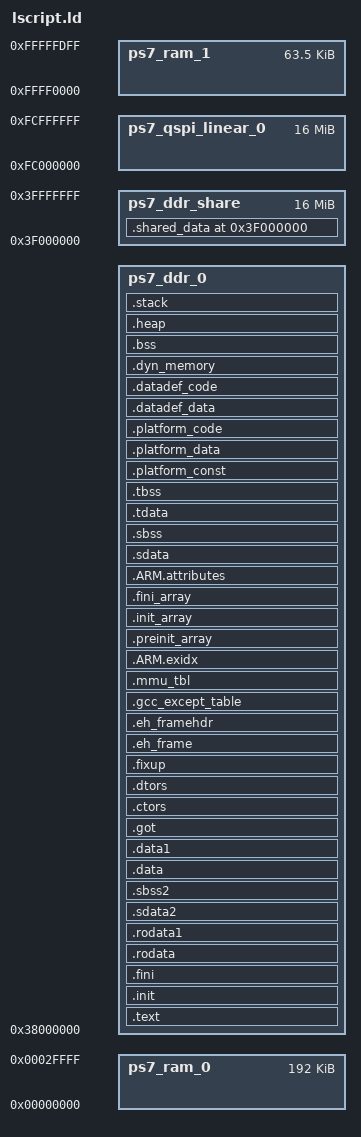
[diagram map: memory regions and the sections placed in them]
/*******************************************************************/
/*                                                                 */
/* This file is automatically generated by linker script generator.*/
/*                                                                 */
/* Version: 2018.3                                                 */
/*                                                                 */
/* Copyright (c) 2010-2016 Xilinx, Inc.  All rights reserved.      */
/*                                                                 */
/* Description : Cortex-A9 Linker Script                           */
/*                                                                 */
/*******************************************************************/

_STACK_SIZE = DEFINED(_STACK_SIZE) ? _STACK_SIZE : 0x8000;
_HEAP_SIZE = DEFINED(_HEAP_SIZE) ? _HEAP_SIZE : 0x402000;

_ABORT_STACK_SIZE = DEFINED(_ABORT_STACK_SIZE) ? _ABORT_STACK_SIZE : 4096;
_SUPERVISOR_STACK_SIZE = DEFINED(_SUPERVISOR_STACK_SIZE) ? _SUPERVISOR_STACK_SIZE : 4096;
_IRQ_STACK_SIZE = DEFINED(_IRQ_STACK_SIZE) ? _IRQ_STACK_SIZE : 8192;
_FIQ_STACK_SIZE = DEFINED(_FIQ_STACK_SIZE) ? _FIQ_STACK_SIZE : 8192;
_UNDEF_STACK_SIZE = DEFINED(_UNDEF_STACK_SIZE) ? _UNDEF_STACK_SIZE : 4096;

/*
  DDR内存空间分配
    DDR总空间 1024M，即0x40000000
    其中：
      0x00000000 ~ 0x38000000 : Linux内存 384M
      0x38000000 ~ 0x3F000000 : 裸核内存  112M
      0x3F000000 ~ 0x40000000 : 共享内存和FPGA使用的内存 16M
*/

/* 当前使用的DDR起始地址 如果这里修改了，需要同时修改bmrun.c文件*/
_CORE1_DDR_START_ADDR =         0x38000000;

/* 如果这里修改了，需要同事修改plt_pub_struct.h文件 */
_CORE1_DDR_SHART_START_ADDR =   0x3F000000;

/* 当前使用的DDR长度 112M        0x7000000 */
_CORE1_DDR_LENGTH =             (_CORE1_DDR_SHART_START_ADDR - _CORE1_DDR_START_ADDR);
/* 当前共享内存的长度 16M 这段内存不开cache 如果这里修改了，需要同时修改plt_pub_struct.h文件 */
_CORE1_DDR_SHARE_LENGTH =       0x1000000;

/*定义堆起始空间 (堆后还有栈空间)*/
_CORE1_HEAP_START_ADDR =  _CORE1_DDR_START_ADDR + _CORE1_DDR_LENGTH - 0x500000; /*最后1M空间用于heap和stack*/
/* 堆和栈之间预留空间 */



_CORE1_HEAP_RESERVE_STACK_SIZE = 0x1000;
/*定义栈起始空间 先放大_HEAP_SIZE 4M 后面考虑用mem_Malloc */
_CORE1_STACK_START_ADDR =  _CORE1_HEAP_START_ADDR + _HEAP_SIZE + _CORE1_HEAP_RESERVE_STACK_SIZE;

/* 定义平台代码各区段之间的预留空间 */
_CORE1_PLATFORM_RESERVE = 0x200;

/* Define Memories in the system */

MEMORY
{
   ps7_ddr_0 : ORIGIN = _CORE1_DDR_START_ADDR, LENGTH = _CORE1_DDR_LENGTH
   ps7_ddr_share : ORIGIN = _CORE1_DDR_SHART_START_ADDR, LENGTH = _CORE1_DDR_SHARE_LENGTH
   ps7_qspi_linear_0 : ORIGIN = 0xFC000000, LENGTH = 0x1000000
   ps7_ram_0 : ORIGIN = 0x0, LENGTH = 0x30000
   ps7_ram_1 : ORIGIN = 0xFFFF0000, LENGTH = 0xFE00
}

/* Specify the default entry point to the program */

ENTRY(_vector_table)

/* Define the sections, and where they are mapped in memory */

SECTIONS
{

.text : {
   KEEP (*(.vectors))
   *(.boot)
   *(.text)
   *(.text.*)
   *(.gnu.linkonce.t.*)
   *(.plt)
   *(.gnu_warning)
   *(.gcc_execpt_table)
   *(.glue_7)
   *(.glue_7t)
   *(.vfp11_veneer)
   *(.ARM.extab)
   *(.gnu.linkonce.armextab.*)
} > ps7_ddr_0

.init : {
   KEEP (*(.init))
} > ps7_ddr_0

.fini : {
   KEEP (*(.fini))
} > ps7_ddr_0

.rodata : {
   __rodata_start = .;
   *(.rodata)
   *(.rodata.*)
   *(.gnu.linkonce.r.*)
   __rodata_end = .;
} > ps7_ddr_0

.rodata1 : {
   __rodata1_start = .;
   *(.rodata1)
   *(.rodata1.*)
   __rodata1_end = .;
} > ps7_ddr_0

.sdata2 : {
   __sdata2_start = .;
   *(.sdata2)
   *(.sdata2.*)
   *(.gnu.linkonce.s2.*)
   __sdata2_end = .;
} > ps7_ddr_0

.sbss2 : {
   __sbss2_start = .;
   *(.sbss2)
   *(.sbss2.*)
   *(.gnu.linkonce.sb2.*)
   __sbss2_end = .;
} > ps7_ddr_0

.data : {
   __data_start = .;
   *(.data)
   *(.data.*)
   *(.gnu.linkonce.d.*)
   *(.jcr)
   *(.got)
   *(.got.plt)
   __data_end = .;
} > ps7_ddr_0

.data1 : {
   __data1_start = .;
   *(.data1)
   *(.data1.*)
   __data1_end = .;
} > ps7_ddr_0

.got : {
   *(.got)
} > ps7_ddr_0

.ctors : {
   __CTOR_LIST__ = .;
   ___CTORS_LIST___ = .;
   KEEP (*crtbegin.o(.ctors))
   KEEP (*(EXCLUDE_FILE(*crtend.o) .ctors))
   KEEP (*(SORT(.ctors.*)))
   KEEP (*(.ctors))
   __CTOR_END__ = .;
   ___CTORS_END___ = .;
} > ps7_ddr_0

.dtors : {
   __DTOR_LIST__ = .;
   ___DTORS_LIST___ = .;
   KEEP (*crtbegin.o(.dtors))
   KEEP (*(EXCLUDE_FILE(*crtend.o) .dtors))
   KEEP (*(SORT(.dtors.*)))
   KEEP (*(.dtors))
   __DTOR_END__ = .;
   ___DTORS_END___ = .;
} > ps7_ddr_0

.fixup : {
   __fixup_start = .;
   *(.fixup)
   __fixup_end = .;
} > ps7_ddr_0

.eh_frame : {
   *(.eh_frame)
} > ps7_ddr_0

.eh_framehdr : {
   __eh_framehdr_start = .;
   *(.eh_framehdr)
   __eh_framehdr_end = .;
} > ps7_ddr_0

.gcc_except_table : {
   *(.gcc_except_table)
} > ps7_ddr_0

.mmu_tbl (ALIGN(16384)) : {
   __mmu_tbl_start = .;
   *(.mmu_tbl)
   __mmu_tbl_end = .;
} > ps7_ddr_0

.ARM.exidx : {
   __exidx_start = .;
   *(.ARM.exidx*)
   *(.gnu.linkonce.armexidix.*.*)
   __exidx_end = .;
} > ps7_ddr_0

.preinit_array : {
   __preinit_array_start = .;
   KEEP (*(SORT(.preinit_array.*)))
   KEEP (*(.preinit_array))
   __preinit_array_end = .;
} > ps7_ddr_0

.init_array : {
   __init_array_start = .;
   KEEP (*(SORT(.init_array.*)))
   KEEP (*(.init_array))
   __init_array_end = .;
} > ps7_ddr_0

.fini_array : {
   __fini_array_start = .;
   KEEP (*(SORT(.fini_array.*)))
   KEEP (*(.fini_array))
   __fini_array_end = .;
} > ps7_ddr_0

.ARM.attributes : {
   __ARM.attributes_start = .;
   *(.ARM.attributes)
   __ARM.attributes_end = .;
} > ps7_ddr_0

.sdata : {
   __sdata_start = .;
   *(.sdata)
   *(.sdata.*)
   *(.gnu.linkonce.s.*)
   __sdata_end = .;
} > ps7_ddr_0

.sbss (NOLOAD) : {
   __sbss_start = .;
   *(.sbss)
   *(.sbss.*)
   *(.gnu.linkonce.sb.*)
   __sbss_end = .;
} > ps7_ddr_0

.tdata : {
   __tdata_start = .;
   *(.tdata)
   *(.tdata.*)
   *(.gnu.linkonce.td.*)
   __tdata_end = .;
} > ps7_ddr_0

.tbss : {
   __tbss_start = .;
   *(.tbss)
   *(.tbss.*)
   *(.gnu.linkonce.tb.*)
   __tbss_end = .;
} > ps7_ddr_0


_SDA_BASE_ = __sdata_start + ((__sbss_end - __sdata_start) / 2 );

_SDA2_BASE_ = __sdata2_start + ((__sbss2_end - __sdata2_start) / 2 );

/* 定义平台代码空间 */

.platform_const : {
   . += _CORE1_PLATFORM_RESERVE;
   __platform_const_start = .;
   *(.platform_const)
   *(.platform_const.*)
   *(.datadef_const)
   *(.datadef_const.*)
   __platform_const_end = .;
} > ps7_ddr_0

.platform_data : {
   . += _CORE1_PLATFORM_RESERVE;
   __platform_data_start = .;
   *(.platform_data)
   *(.platform_data.*)
   __platform_data_end = .;
} > ps7_ddr_0

.platform_code : {
   . += _CORE1_PLATFORM_RESERVE;
   __platform_code_start = .;
   *(.platform_code)
   *(.platform_code.*)
   __platform_code_end = .;
} > ps7_ddr_0

.datadef_data : {
   . += _CORE1_PLATFORM_RESERVE;
   __datadef_data_start = .;
   *(.datadef_data)
   *(.datadef_data.*)
   __datadef_data_end = .;
} > ps7_ddr_0

.datadef_code : {
   . += _CORE1_PLATFORM_RESERVE;
   __datadef_code_start = .;
   *(.datadef_code)
   *(.datadef_code.*)
   __datadef_code_end = .;
} > ps7_ddr_0

.dyn_memory (NOLOAD) : {
   . += _CORE1_PLATFORM_RESERVE;
   __dyn_memory_start = .;
   *(.dyn_memory)
   *(.dyn_memory*)
   __dyn_memory_end = .;
} > ps7_ddr_0

.bss (NOLOAD) : {
   __bss_start = .;
   *(.bss)
   *(.bss.*)
   *(.gnu.linkonce.b.*)
   *(COMMON)
   __bss_end = .;
} > ps7_ddr_0

/* Generate Stack and Heap definitions */

.heap _CORE1_HEAP_START_ADDR (NOLOAD) : {
   . = ALIGN(16);
   _heap = .;
   HeapBase = .;
   _heap_start = .;
   . += _HEAP_SIZE;
   _heap_end = .;
   HeapLimit = .;
} > ps7_ddr_0

.stack _CORE1_STACK_START_ADDR (NOLOAD) : {
   . = ALIGN(16);
   _stack_end = .;
   . += _STACK_SIZE;
   . = ALIGN(16);
   _stack = .;
   __stack = _stack;
   . = ALIGN(16);
   _irq_stack_end = .;
   . += _IRQ_STACK_SIZE;
   . = ALIGN(16);
   __irq_stack = .;
   _supervisor_stack_end = .;
   . += _SUPERVISOR_STACK_SIZE;
   . = ALIGN(16);
   __supervisor_stack = .;
   _abort_stack_end = .;
   . += _ABORT_STACK_SIZE;
   . = ALIGN(16);
   __abort_stack = .;
   _fiq_stack_end = .;
   . += _FIQ_STACK_SIZE;
   . = ALIGN(16);
   __fiq_stack = .;
   _undef_stack_end = .;
   . += _UNDEF_STACK_SIZE;
   . = ALIGN(16);
   __undef_stack = .;
} > ps7_ddr_0

/** 无cache的内存段 **/
.shared_data _CORE1_DDR_SHART_START_ADDR (NOLOAD) : {
   /* BM与Linux交互内存空间 */
   __shared_data_start = .;
   *(.shared_data)
   *(.shared_data*)
   __shared_data_end = .;

   /* 非cache内存空间，BM独占 */
   . = ALIGN(0x10000);
   __no_cache_start = .;
   *(.no_cache)
   *(.no_cache*)
   __no_cache_end = .;
} > ps7_ddr_share

_end = .;

}

